# RT584ZCM33 register map
Series: ARMv8-M Mainline; File version: 1.0
CPU: CM33 r0p0, little endian, MPU, no FPU, VTOR, 3 interrupt priority bits
Registers are 32-bit, read-write, reset 0x0 unless marked. A register's access mark holds for its fields unless they carry their own. Offsets are from the block's base; [hi:lo] are bit positions; 'fields as' and 'values as' point back to an identical list; <NAME> marks a mode.

## PWM0_Non-Secure — PWM0 Non-Secure Register block
Base 0x40026000
Same registers: PWM1_Non-Secure 0x40026100, PWM2_Non-Secure 0x40026200, PWM3_Non-Secure 0x40026300, PWM4_Non-Secure 0x40026400, PWM0_Secure 0x50026000, PWM1_Secure 0x50026100, PWM2_Secure 0x50026200, PWM3_Secure 0x50026300, PWM4_Secure 0x50026400
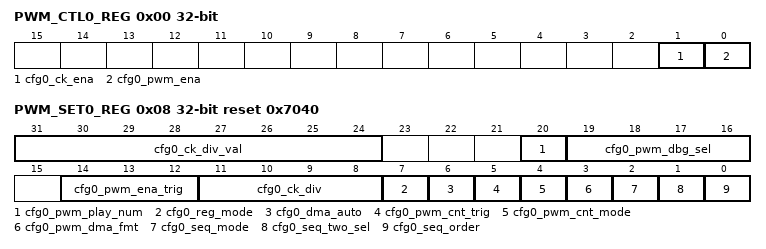
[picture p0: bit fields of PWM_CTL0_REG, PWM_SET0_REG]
0x00 PWM_CTL0_REG — pwm ctl0
  [1] cfg0_ck_ena — Enable pwm gated clock 0: disable 1: enable
    0=B_1_ITEM0 (disable); 1=B_1_ITEM1 (enable)
  [0] cfg0_pwm_ena — Enable pwm 0: disable 1: enable
    0=B_0_ITEM0 (disable); 1=B_0_ITEM1 (enable)
0x04 PWM_CTL1_REG wo — pwm ctl1
  [0] cfg0_pwm_rst — Write 1 to reset pwm
    0=B_0 (Write 1 to reset pwm)
0x08 PWM_SET0_REG reset 0x7040 — pwm set0
  [31:24] cfg0_ck_div_val — PWM gated clock divider value, only valid when >0
    0=B_24_to_31 (PWM gated clock divider value, only valid when >0)
  [20] cfg0_pwm_play_num — PWM regstermode data play number, used in register mode 0: 1 data 1: 2 data
    0=B_20_ITEM0 (1 data); 1=B_20_ITEM1 (2 data)
  [19:16] cfg0_pwm_dbg_sel — Debug monitor selection
    0=B_16_to_19 (Debug monitor selection)
  [14:12] cfg0_pwm_ena_trig — PWM counter enable trigger by other PWM Note: if cfgX_seqx_cnt is 65535, trigger whenever PWMX 1st sequence finish where X is 0~4. 0: trigger whenever PWM0 sequence finish 1: trigger whenever PWM1 sequence finish 2: trigger whenever PWM2 sequence finish 3: trigger whenever PWM3 sequence finish 4: trigger whenever PWM4 sequence finish others: self-trigger
    0=B_12_to_14 (PWM counter enable trigger by other PWM Note: if cfgX_seqx_cnt is 65535, trigger whenever PWMX 1st sequence finish where X is 0~4. 0: trigger whenever PWM0 sequence finish 1: trigger whenever PWM1 sequence finish 2: trigger whenever PWM2 sequence finish 3: trigger whenever PWM3 sequence finish 4: trigger whenever PWM4 sequence finish others: self-trigger)
  [11:8] cfg0_ck_div — PWM gated clock divider value 0: clock divided by 1 1: clock divided by 2 2: clock divided by 4 3: clock divided by 8 4: clock divided by 16 5: clock divided by 32 6: clock divided by 64 7: clock divided by 128 8: clock divided by 256 otherwise: clock divided by 256 only valid when cfg0_ck_div_val=0
    0=B_8_to_11 (PWM gated clock divider value 0: clock divided by 1 1: clock divided by 2 2: clock divided by 4 3: clock divided by 8 4: clock divided by 16 5: clock divided by 32 6: clock divided by 64 7: clock divided by 128 8: clock divided by 256 otherwise: clock divided by 256 only valid when cfg0_ck_div_val=0)
  [7] cfg0_reg_mode — PWM register mode settomg, used in register mode 0:DMA mode 1:register mode
    0=B_7_ITEM0 (DMA mode); 1=B_7_ITEM1 (register mode)
  [6] cfg0_dma_auto — Auto Trigger start DMA when the amount of playback 2-sequence play does not reache cfgx_seqx_pcnt 0: No auto trigger 1: Auto trigger
    0=B_6_ITEM0 (No auto trigger); 1=B_6_ITEM1 (Auto trigger)
  [5] cfg0_pwm_cnt_trig — PWM counter trigger, set to 1 in register mode 0: trigger by cfg_pwm_ena and FIFO is not empty 1: trigger by cfg_pwm_ena
    0=B_5_ITEM0 (trigger by cfg_pwm_ena and FIFO is not empty); 1=B_5_ITEM1 (trigger by cfg_pwm_ena)
  [4] cfg0_pwm_cnt_mode — PWM counter mode, used in register mode 0: Up counter 1: Up and down counter
    0=B_4_ITEM0 (Up counter); 1=B_4_ITEM1 (Up and down counter)
  [3] cfg0_pwm_dma_fmt — PWM dma sample format, used in register mode 0: Format-0, 32-bit is [PHA(N), THD(N), PHA(N-1), THD(N-1)] 1: Format-1, 32-bit is [1'b0, CNT_END(N), PHA(N), THD(N)]
    0=B_3_ITEM0 (Format-0, 32-bit is [PHA(N), THD(N), PHA(N-1), THD(N-1)]); 1=B_3_ITEM1 (Format-1, 32-bit is [1'b0, CNT_END(N), PHA(N), THD(N)])
  [2] cfg0_seq_mode — PWM sequence play mode, used in register mode 0: non-continuous play 1: continuous play
    0=B_2_ITEM0 (non-continuous play); 1=B_2_ITEM1 (continuous play)
  [1] cfg0_seq_two_sel — Two Sequence selection 0: One sequence 1: Two sequence
    0=B_1_ITEM0 (One sequence); 1=B_1_ITEM1 (Two sequence)
  [0] cfg0_seq_order — PWM sequence play order 0: RSEQ 1st 1: TSEQ 1st
    0=B_0_ITEM0 (RSEQ 1st); 1=B_0_ITEM1 (TSEQ 1st)
0x0C PWM_SET1_REG — pwm set1
  [14:0] cfg0_pwm_cnt_end — PWM counter end value, ignored when cfg0_pwm_dma_fmt is at Format-1 value: 3 to 32767
0x10 PWM_SET2_REG — pwm set2
  [15:0] cfg0_seqx_pcnt — Amount of sequence play 0: Play one/two sequence with 1-times (zero protection) 1: Play one/two sequence with 1-times 65534: Play one/two sequence with 65534-times
0x14 PWM_SET3_REG — pwm set3
  [15:0] cfg0_seq0_num — Number of element in RSEQ
0x18 PWM_SET4_REG — pwm set4
  [23:0] cfg0_seq0_rpt — Number of repeat for each element in RSEQ
0x1C PWM_SET5_REG — pwm set5
  [23:0] cfg0_seq0_dly — Number of delay after RSEQ is play finish
0x20 PWM_SET6_REG — pwm set6
  [15:0] cfg0_seq1_num — Number of element in TSEQ
0x24 PWM_SET7_REG — pwm set7
  [23:0] cfg0_seq1_rpt — Number of repeat for each element in TSEQ
0x28 PWM_SET8_REG — pwm set8
  [23:0] cfg0_seq1_dly — Number of delay after TSEQ is play finish
0x40 PWM_RDMA0_CTL0_REG wo — pwm rdma0 ctl0
  [3:0] cfg0_pwm_rdma0_ctl0 — Writre 1 to the bit 0 to start xdma for memory read access. Other bits are reserved.
    0=B_0_to_3 (Writre 1 to the bit 0 to start xdma for memory read access. Other bits are reserved.)
0x44 PWM_RDMA0_CTL1_REG wo — pwm rdma0 ctl1
  [0] cfg0_pwm_rdma0_ctl1 — Write 1 to xdma read.
    0=B_0 (Write 1 to xdma read.)
0x48 PWM_RDMA0_SET0_REG — [15:0] Segment size, 4-byte aligned 0: Illegal value Others: 1 to 65535 (Block size < Segment size) [31:16] Block size, 4-byte aligned 0: Single-shot mode Others: 1 to 65535 (Block size < Segment size)
0x4C PWM_RDMA0_SET1_REG — start address point, 4-byte aligned The 2-LSB bit will be ignored
0x50 PWM_RDMA0_SET2_REG — pwm rdma0 set2
  [7:0] cfg0_pwm_rdma0_set2 — [0] Set initial address 0: when xdma start, initial address is loaded from ptr 1: when xdma reset, initial address is loaded from ptr [3:1] Reserved [5:4] DMA data format 0: word, 4-bytes aligned 1: halfword, 2-bytes aligned 2/3: 1-byte aligned [7:6] Reserved
    0=B_0_to_7 ([0] Set initial address 0: when xdma start, initial address is loaded from ptr 1: when xdma reset, initial address is loaded from ptr [3:1] Reserved [5:4] DMA data format 0: word, 4-bytes aligned 1: halfword, 2-bytes aligned 2/3: 1-byte aligned [7:6] Reserved)
0x58 PWM_RDMA0_R0_REG ro — Status of xdma next pointer address
0x5C PWM_RDMA0_R1_REG ro — [0] xdma interrupt status [1] xdma error interrupt status [2] OR(xdma interrupt status, xdma error interrupt status) [9:8] xdma counter status, used for ping-pong buffer to check buffer status [16] xdma enable [17] xdma_done [19:18] xdma_status
0x60 PWM_RDMA1_CTL0_REG wo — pwm rdma1 ctl0
  [3:0] cfg0_pwm_rdma1_ctl0 — Writre 1 to the bit 0 to start xdma for memory read access. Other bits are reserved.
    values as PWM_RDMA0_CTL0_REG.cfg0_pwm_rdma0_ctl0
0x64 PWM_RDMA1_CTL1_REG wo — pwm rdma1 ctl1
  [0] cfg0_pwm_rdma1_ctl1 — Write 1 to xdma read.
    0=B_0 (Write 1 to xdma read.)
0x68 PWM_RDMA1_SET0_REG — [15:0] Segment size, 4-byte aligned 0: Illegal value Others: 1 to 65535 (Block size < Segment size) [31:16] Block size, 4-byte aligned 0: Single-shot mode Others: 1 to 65535 (Block size < Segment size)
0x6C PWM_RDMA1_SET1_REG — start address point, 4-byte aligned The 2-LSB bit will be ignored
0x70 PWM_RDMA1_SET2_REG — pwm rdma1 set2
  [7:0] cfg0_pwm_rdma1_set2 — [0] Set initial address 0: when xdma start, initial address is loaded from ptr 1: when xdma reset, initial address is loaded from ptr [3:1] Reserved [5:4] DMA data format 0: word, 4-bytes aligned 1: halfword, 2-bytes aligned 2/3: 1-byte aligned [7:6] Reserved
    values as PWM_RDMA0_SET2_REG.cfg0_pwm_rdma0_set2
0x78 PWM_RDMA1_R0_REG ro — Status of xdma next pointer address
0x7C PWM_RDMA1_R1_REG ro — [0] xdma interrupt status [1] xdma error interrupt status [2] OR(xdma interrupt status, xdma error interrupt status) [9:8] xdma counter status, used for ping-pong buffer to check buffer status [16] xdma enable [17] xdma_done [19:18] xdma_status
0xA0 PWM_INT_CLEAR_REG wo — pwm int clear
  [7:0] cfg0_pwm_int_clear — [0] Clear RDMA0 interrpt; 1: clear [1] Clear RDMA0 error interrupt; 1: clear [2] Clear RDMA1 interrpt; 1: clear [3] Clear RDMA1 error interrupt; 1: clear [4] Clear RSEQ done interrupt; 1: clear [5] Clear TSEQ done interrupt; 1: clear [6] Clear one/two sequence*cfgx_seqx_pcnt done interrupt; 1: clear [7] Clear reg mode interrupt; 1: clear
    0=B_0_to_7 ([0] Clear RDMA0 interrpt; 1: clear [1] Clear RDMA0 error interrupt; 1: clear [2] Clear RDMA1 interrpt; 1: clear [3] Clear RDMA1 error interrupt; 1: clear [4] Clear RSEQ done interrupt; 1: clear [5] Clear TSEQ done interrupt; 1: clear [6] Clear one/two sequence*cfgx_seqx_pcnt done interrupt; 1: clear [7] Clear reg mode interrupt; 1: clear)
0xA4 PWM_INT_MASK_REG reset 0x70 — pwm int mask
  [7:0] cfg0_pwm_int_mask — [0] Mask RDMA0 interrpt; 0: No mask 1: Mask [1] Mask RDMA0 error interrupt; 0: No mask 1: Mask [2] Mask RDMA1 interrpt; 0: No mask 1: Mask [3] Mask RDMA1 error interrupt; 0: No mask 1: Mask [4] Mask RSEQ done interrupt; 0: No mask 1: Mask [5] Mask TSEQ done interrupt; 0: No mask 1: Mask [6] Mask one/two sequence*cfgx_seqx_pcnt done interrupt;0: No mask 1: Mask [7] Mask reg mode interrupt; 0: No mask 1: Mask
    0=B_0_to_7 ([0] Mask RDMA0 interrpt; 0: No mask 1: Mask [1] Mask RDMA0 error interrupt; 0: No mask 1: Mask [2] Mask RDMA1 interrpt; 0: No mask 1: Mask [3] Mask RDMA1 error interrupt; 0: No mask 1: Mask [4] Mask RSEQ done interrupt; 0: No mask 1: Mask [5] Mask TSEQ done interrupt; 0: No mask 1: Mask [6] Mask one/two sequence*cfgx_seqx_pcnt done interrupt;0: No mask 1: Mask [7] Mask reg mode interrupt; 0: No mask 1: Mask)
0xA8 PWM_INT_STATUS_REG ro — pwm int status
  [7:0] cfg0_pwm_int_status — [0] Status of RDMA0 interrupt [1] Status of RDMA0 error interrupt [2] Status of RDMA1 interrupt [3] Status of RDMA1 error interrupt [4] Status of RSEQ done interrupt; [5] Status of TSEQ done interrupt; [6] Status of one/two sequence*cfgx_seqx_pcnt done interrupt; [7] Status of reg mode interrupt;
    0=B_0_to_7 ([0] Status of RDMA0 interrupt [1] Status of RDMA0 error interrupt [2] Status of RDMA1 interrupt [3] Status of RDMA1 error interrupt [4] Status of RSEQ done interrupt; [5] Status of TSEQ done interrupt; [6] Status of one/two sequence*cfgx_seqx_pcnt done interrupt; [7] Status of reg mode interrupt;)
0xAC PWM_REG_D0_REG — PWM regster mode data0
0xB0 PWM_REG_D1_REG — PWM regster mode data1
